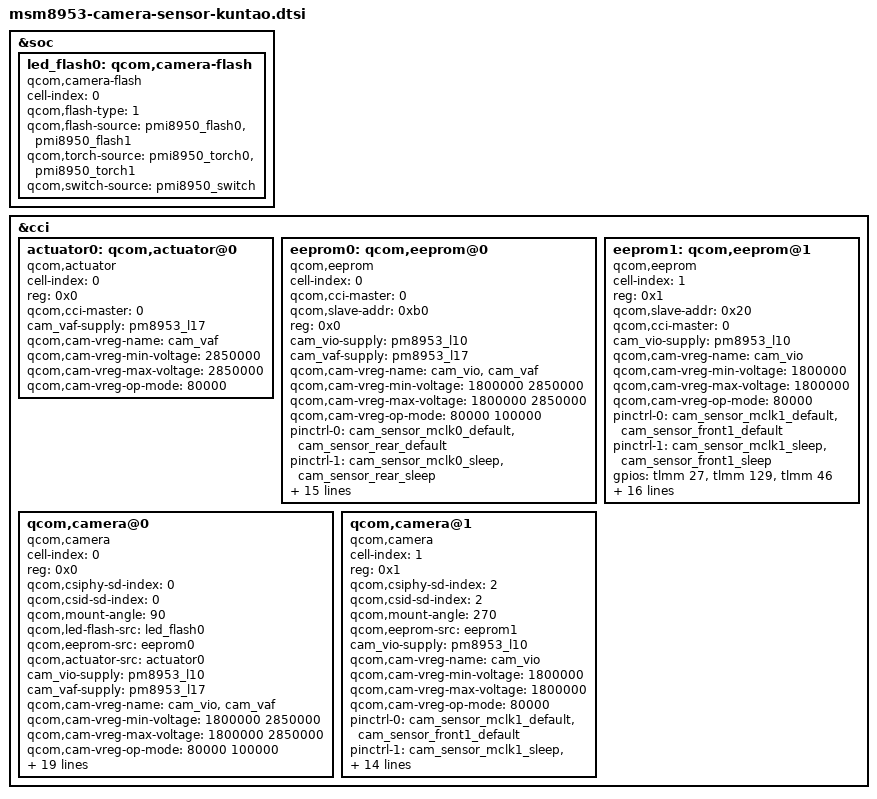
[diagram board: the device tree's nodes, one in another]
/*
 * Copyright (c) 2015-2016, The Linux Foundation. All rights reserved.
 *
 * This program is free software; you can redistribute it and/or modify
 * it under the terms of the GNU General Public License version 2 and
 * only version 2 as published by the Free Software Foundation.
 *
 * This program is distributed in the hope that it will be useful,
 * but WITHOUT ANY WARRANTY; without even the implied warranty of
 * MERCHANTABILITY or FITNESS FOR A PARTICULAR PURPOSE.  See the
 * GNU General Public License for more details.
 */

&soc {
	led_flash0: qcom,camera-flash {
		cell-index = <0>;
		compatible = "qcom,camera-flash";
		qcom,flash-type = <1>;
		qcom,flash-source = <&pmi8950_flash0 &pmi8950_flash1>;
		qcom,torch-source = <&pmi8950_torch0 &pmi8950_torch1>;
		qcom,switch-source = <&pmi8950_switch>;
	};
};

&cci {
	actuator0: qcom,actuator@0 {
		cell-index = <0>;
		reg = <0x0>;
		compatible = "qcom,actuator";
		qcom,cci-master = <0>;
		cam_vaf-supply = <&pm8953_l17>;
		qcom,cam-vreg-name = "cam_vaf";
		qcom,cam-vreg-min-voltage = <2850000>;
		qcom,cam-vreg-max-voltage = <2850000>;
		qcom,cam-vreg-op-mode = <80000>;
	};

	eeprom0: qcom,eeprom@0 {
		cell-index = <0>;
		compatible = "qcom,eeprom";
		qcom,cci-master = <0>;
		qcom,slave-addr = <0xb0>;
		reg = <0x0>;
		cam_vio-supply = <&pm8953_l10>;
		cam_vaf-supply = <&pm8953_l17>;
		qcom,cam-vreg-name = "cam_vio", "cam_vaf";
		qcom,cam-vreg-min-voltage = <1800000 2850000 >;
		qcom,cam-vreg-max-voltage = <1800000 2850000 >;
		qcom,cam-vreg-op-mode = <80000 100000>;
		pinctrl-names = "cam_default", "cam_suspend";
		pinctrl-0 = <&cam_sensor_mclk0_default
			&cam_sensor_rear_default>;
		pinctrl-1 = <&cam_sensor_mclk0_sleep &cam_sensor_rear_sleep>;
		gpios = <&tlmm 26 0>,
			<&tlmm 39 0>,
			<&tlmm 46 0>;
		qcom,gpio-standby = <1>;
		qcom,gpio-vdig = <2>;
		qcom,gpio-req-tbl-num = <0 1 2>;
		qcom,gpio-req-tbl-flags = <1 0 0>;
		qcom,gpio-req-tbl-label = "CAMIF_MCLK0",
			"CAM_STANDBY0",
			"CAM_VDIG";
		status = "ok";
		qcom,cam-power-seq-type = "sensor_vreg","sensor_vreg";
		qcom,cam-power-seq-val = "cam_vio","cam_vaf";
		qcom,cam-power-seq-cfg-val = <1 1>;
		qcom,cam-power-seq-delay = <5 5>;
		clocks = <&clock_gcc clk_mclk0_clk_src>,
			<&clock_gcc clk_gcc_camss_mclk0_clk>;
		clock-names = "cam_src_clk", "cam_clk";
		qcom,clock-rates = <19200000 0>;
	};

	eeprom1: qcom,eeprom@1 {
		cell-index = <1>;
		reg = <0x1>;
		compatible = "qcom,eeprom";
		qcom,slave-addr = <0x20>;
		qcom,cci-master = <0>;
		cam_vio-supply = <&pm8953_l10>;
		qcom,cam-vreg-name = "cam_vio";
		qcom,cam-vreg-min-voltage = <1800000>;
		qcom,cam-vreg-max-voltage = <1800000>;
		qcom,cam-vreg-op-mode = <80000>;
		pinctrl-names = "cam_default", "cam_suspend";
		pinctrl-0 = <&cam_sensor_mclk1_default
			&cam_sensor_front1_default>;
		pinctrl-1 = <&cam_sensor_mclk1_sleep &cam_sensor_front1_sleep>;
		gpios = <&tlmm 27 0>,
			<&tlmm 129 0>,
			<&tlmm 46 0>;
		qcom,gpio-reset = <1>;
		qcom,gpio-vdig = <2>;
		qcom,gpio-req-tbl-num = <0 1 2>;
		qcom,gpio-req-tbl-flags = <1 0 0>;
		qcom,gpio-req-tbl-label = "CAMIF_MCLK1",
			"CAM_RESET1",
			"CAM_VDIG";
		qcom,cam-power-seq-type = "sensor_vreg",
			"sensor_gpio","sensor_gpio" , "sensor_clk";
		qcom,cam-power-seq-val =  "cam_vio", "sensor_gpio_vdig",
			"sensor_gpio_reset", "sensor_cam_mclk";
		qcom,cam-power-seq-cfg-val = <1 1 1 24000000>;
		qcom,cam-power-seq-delay = <1 1 5 5>;
		clocks = <&clock_gcc clk_mclk1_clk_src>,
			<&clock_gcc clk_gcc_camss_mclk1_clk>;
		clock-names = "cam_src_clk", "cam_clk";
		qcom,clock-rates = <24000000 0>;
	};

	qcom,camera@0 {
		cell-index = <0>;
		compatible = "qcom,camera";
		reg = <0x0>;
		qcom,csiphy-sd-index = <0>;
		qcom,csid-sd-index = <0>;
		qcom,mount-angle = <90>;
		qcom,led-flash-src = <&led_flash0>;
		qcom,eeprom-src = <&eeprom0>;
		qcom,actuator-src = <&actuator0>;
		cam_vio-supply = <&pm8953_l10>;
		cam_vaf-supply = <&pm8953_l17>;
		qcom,cam-vreg-name = "cam_vio", "cam_vaf";
		qcom,cam-vreg-min-voltage = <1800000 2850000 >;
		qcom,cam-vreg-max-voltage = <1800000 2850000 >;
		qcom,cam-vreg-op-mode = <80000 100000>;
		pinctrl-names = "cam_default", "cam_suspend";
		pinctrl-0 = <&cam_sensor_mclk0_default &cam_sensor_rear_default
			&cam_sensor_rear_vana>;
		pinctrl-1 = <&cam_sensor_mclk0_sleep &cam_sensor_rear_sleep
			&cam_sensor_rear_vana_sleep>;
		gpios = <&tlmm 26 0>,
			<&tlmm 39 0>,
			<&tlmm 46 0>;
		qcom,gpio-standby = <1>;
		qcom,gpio-vdig = <2>;
		qcom,gpio-req-tbl-num = <0 1 2>;
		qcom,gpio-req-tbl-flags = <1 0 0>;
		qcom,gpio-req-tbl-label = "CAMIF_MCLK0",
			"CAM_STANDBY0",
			"CAM_VDIG";
		qcom,sensor-position = <0>;
		qcom,sensor-mode = <0>;
		qcom,cci-master = <0>;
		status = "ok";
		clocks = <&clock_gcc clk_mclk0_clk_src>,
			<&clock_gcc clk_gcc_camss_mclk0_clk>;
		clock-names = "cam_src_clk", "cam_clk";
		qcom,clock-rates = <24000000 0>;
	};

	qcom,camera@1 {
		cell-index = <1>;
		compatible = "qcom,camera";
		reg = <0x1>;
		qcom,csiphy-sd-index = <2>;
		qcom,csid-sd-index = <2>;
		qcom,mount-angle = <270>;
		qcom,eeprom-src = <&eeprom1>;
		cam_vio-supply = <&pm8953_l10>;
		qcom,cam-vreg-name = "cam_vio";
		qcom,cam-vreg-min-voltage = <1800000>;
		qcom,cam-vreg-max-voltage = <1800000>;
		qcom,cam-vreg-op-mode = <80000>;
		pinctrl-names = "cam_default", "cam_suspend";
		pinctrl-0 = <&cam_sensor_mclk1_default
			&cam_sensor_front1_default>;
		pinctrl-1 = <&cam_sensor_mclk1_sleep &cam_sensor_front1_sleep>;
		gpios = <&tlmm 27 0>,
			<&tlmm 129 0>,
			<&tlmm 46 0>;
		qcom,gpio-reset = <1>;
		qcom,gpio-vdig = <2>;
		qcom,gpio-req-tbl-num = <0 1 2>;
		qcom,gpio-req-tbl-flags = <1 0 0>;
		qcom,gpio-req-tbl-label = "CAMIF_MCLK1",
			"CAM_RESET1",
			"CAM_VDIG";
		qcom,sensor-position = <1>;
		qcom,sensor-mode = <0>;
		qcom,cci-master = <0>;
		status = "ok";
		clocks = <&clock_gcc clk_mclk1_clk_src>,
			<&clock_gcc clk_gcc_camss_mclk1_clk>;
		clock-names = "cam_src_clk", "cam_clk";
		qcom,clock-rates = <24000000 0>;
	};
};
